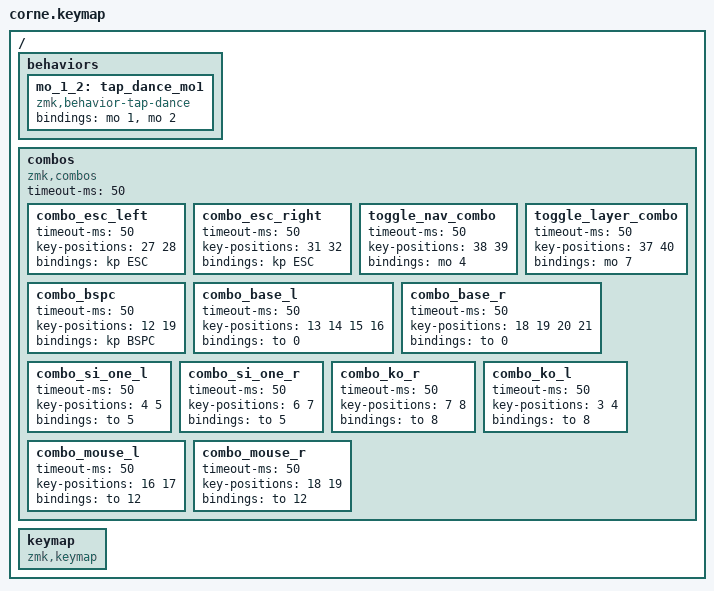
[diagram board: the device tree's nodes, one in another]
#include <behaviors.dtsi>
#include <dt-bindings/zmk/keys.h>
#include <dt-bindings/zmk/pointing.h>
#include <dt-bindings/zmk/bt.h>

#define DEFAULT 0
#define LOWER   1
#define RAISE   2
#define TD_TAPPING_TERM 150


/ {
    behaviors {
        mo_1_2: tap_dance_mo1 { compatible = "zmk,behavior-tap-dance";
            #binding-cells = <0>;
            bindings = <&mo 1>, <&mo 2>;
        };
        /*
        mmv {
            acceleration-exponent = <1>;      // 1
            time-to-max-speed-ms = <300>;    // 40
            delay-ms = <0>;                   // 0
        };
        msc {
            acceleration-exponent = <1>;      // 0
            time-to-max-speed-ms = <40>;      // 500
            delay-ms = <0>;                   // 10
        };
        */
    };
    combos {
        compatible = "zmk,combos";
        timeout-ms = <50>; // How fast the keys must be pressed together
        combo_esc_left {
            timeout-ms = <50>;
            key-positions = <27 28>;
            bindings = <&kp ESC>;
        };
        combo_esc_right {
            timeout-ms = <50>;
            key-positions = <31 32>;
            bindings = <&kp ESC>;
        };
        toggle_nav_combo {
            timeout-ms = <50>;
            key-positions = <38 39>; // Replace with the indices of your two keys
            bindings = <&mo 4>;
        };
        toggle_layer_combo {
            timeout-ms = <50>;
            key-positions = <37 40>; // Replace with the indices of your two keys
            bindings = <&mo 7>;
        };
        /*
        combo_double_space_td {
            timeout-ms = <50>;
            key-positions = <38 39>;  // your two keys
            bindings = <&td_space>;   // triggers the tap dance
        };
        toggle_reverse_base_l {
            timeout-ms = <50>;
            key-positions = <37 38>; // Replace with the indices of your two keys
            bindings = <&mo 2>;
        };
        toggle_reverse_base_r {
            timeout-ms = <50>;
            key-positions = <39 40>; // Replace with the indices of your two keys
            bindings = <&mo 2>;
        };
        */
        combo_bspc {
            timeout-ms = <50>;
            key-positions = <12 19>;
            bindings = <&kp BSPC>;
        };
        combo_base_l {
            timeout-ms = <50>;
            key-positions = <13 14 15 16>;
            bindings = <&to 0>;
        };
        combo_base_r {
            timeout-ms = <50>;
            key-positions = <18 19 20 21>;
            bindings = <&to 0>;
        };
        combo_si_one_l {
            timeout-ms = <50>;
            key-positions = <4 5>;
            bindings = <&to 5>;
        };
        combo_si_one_r {
            timeout-ms = <50>;
            key-positions = <6 7>;
            bindings = <&to 5>;
        };

        combo_ko_r {
            timeout-ms = <50>;
            key-positions = <7 8>;
            bindings = <&to 8>;
        };
        combo_ko_l {
            timeout-ms = <50>;
            key-positions = <3 4>;
            bindings = <&to 8>;
        };
        combo_mouse_l {
            timeout-ms = <50>;
            key-positions = <16 17>;
            bindings = <&to 12>;
        };
        combo_mouse_r {
            timeout-ms = <50>;
            key-positions = <18 19>;
            bindings = <&to 12>;
        };
    };
    keymap {
        compatible = "zmk,keymap";

        #include "layers/default.dtsi"
        #include "layers/r_symbols.dtsi"
        #include "layers/qwerty.dtsi"
        #include "layers/navigation.dtsi"
        #include "layers/si_one.dtsi"
        #include "layers/layer_layer.dtsi"

        #include "layers/konomu.dtsi"
        #include "layers/mouse.dtsi"
    };
};
